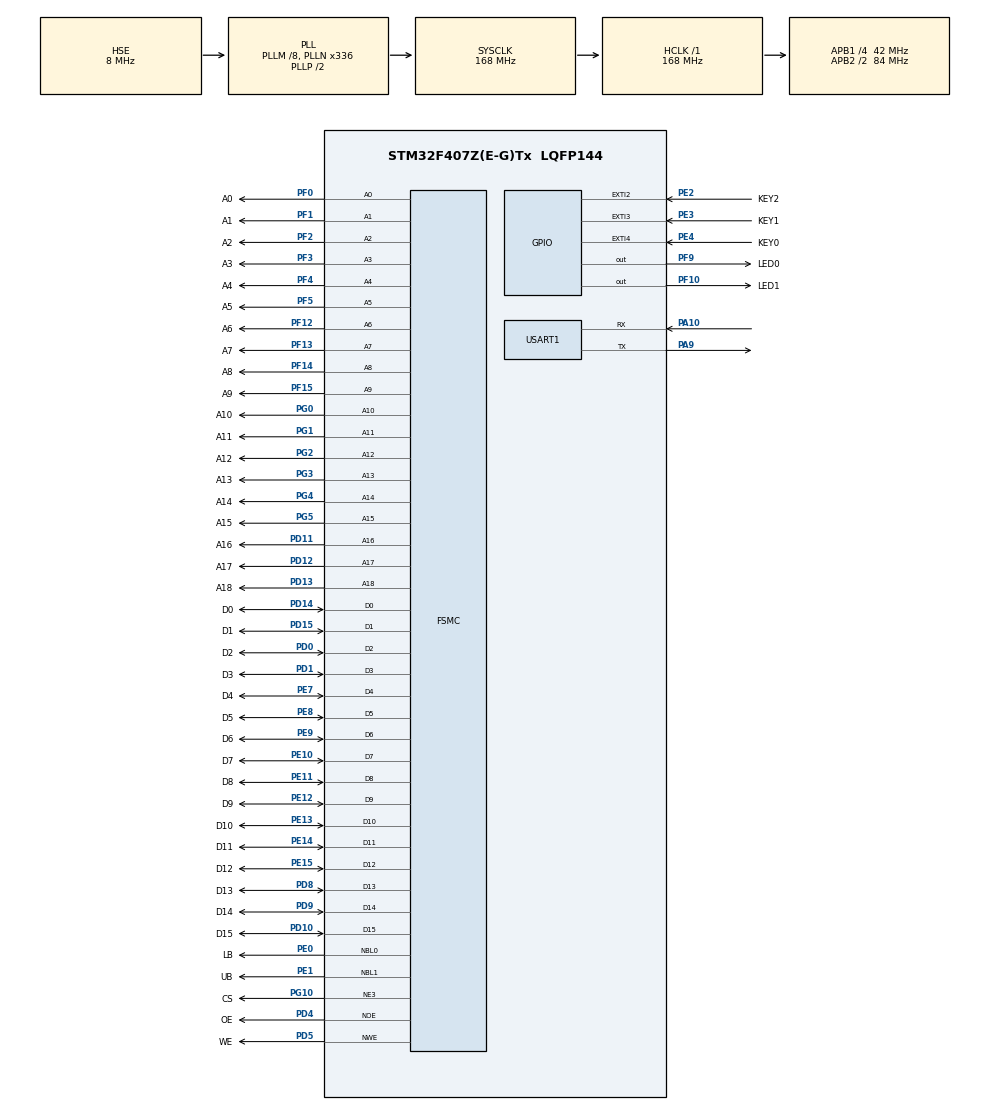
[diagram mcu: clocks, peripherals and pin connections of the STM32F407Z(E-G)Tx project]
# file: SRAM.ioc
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FSMC.AddressSetupTime1=2
FSMC.BusTurnAroundDuration1=0
FSMC.DataSetupTime1=8
FSMC.ExtendedMode1=FSMC_EXTENDED_MODE_DISABLE
FSMC.WriteOperation1=FSMC_WRITE_OPERATION_ENABLE
Mcu.Family=STM32F4
Mcu.Name=STM32F407Z(E-G)Tx
Mcu.Package=LQFP144
NVIC.EXTI2_IRQn=true\:1\:1\:true\:false\:true\:true\:true
NVIC.EXTI3_IRQn=true\:1\:1\:true\:false\:true\:true\:true
NVIC.EXTI4_IRQn=true\:1\:1\:true\:false\:true\:true\:true
NVIC.PriorityGroup=NVIC_PRIORITYGROUP_2
PA10.Mode=Asynchronous
PA10.Signal=USART1_RX
PA13.Mode=Serial_Wire
PA13.Signal=SYS_JTMS-SWDIO
PA14.Mode=Serial_Wire
PA14.Signal=SYS_JTCK-SWCLK
PA9.Mode=Asynchronous
PA9.Signal=USART1_TX
PD0.GPIO_Label=D2
PD0.GPIO_PuPd=GPIO_PULLUP
PD0.Signal=FSMC_D2_DA2
PD1.GPIO_Label=D3
PD1.GPIO_PuPd=GPIO_PULLUP
PD1.Signal=FSMC_D3_DA3
PD10.GPIO_Label=D15
PD10.GPIO_PuPd=GPIO_PULLUP
PD10.Signal=FSMC_D15_DA15
PD11.GPIO_Label=A16
PD11.GPIO_PuPd=GPIO_PULLUP
PD11.Signal=FSMC_A16_CLE
PD12.GPIO_Label=A17
PD12.GPIO_PuPd=GPIO_PULLUP
PD12.Signal=FSMC_A17_ALE
PD13.GPIO_Label=A18
PD13.GPIO_PuPd=GPIO_PULLUP
PD13.Signal=FSMC_A18
PD14.GPIO_Label=D0
PD14.GPIO_PuPd=GPIO_PULLUP
PD14.Signal=FSMC_D0_DA0
PD15.GPIO_Label=D1
PD15.GPIO_PuPd=GPIO_PULLUP
PD15.Signal=FSMC_D1_DA1
PD4.GPIO_Label=OE
PD4.GPIO_PuPd=GPIO_PULLUP
PD4.Signal=FSMC_NOE
PD5.GPIO_Label=WE
PD5.GPIO_PuPd=GPIO_PULLUP
PD5.Signal=FSMC_NWE
PD8.GPIO_Label=D13
PD8.GPIO_PuPd=GPIO_PULLUP
PD8.Signal=FSMC_D13_DA13
PD9.GPIO_Label=D14
PD9.GPIO_PuPd=GPIO_PULLUP
PD9.Signal=FSMC_D14_DA14
PE0.GPIO_Label=LB
PE0.GPIO_PuPd=GPIO_PULLUP
PE0.Signal=FSMC_NBL0
PE1.GPIO_Label=UB
PE1.GPIO_PuPd=GPIO_PULLUP
PE1.Signal=FSMC_NBL1
PE10.GPIO_Label=D7
PE10.GPIO_PuPd=GPIO_PULLUP
PE10.Signal=FSMC_D7_DA7
PE11.GPIO_Label=D8
PE11.GPIO_PuPd=GPIO_PULLUP
PE11.Signal=FSMC_D8_DA8
PE12.GPIO_Label=D9
PE12.GPIO_PuPd=GPIO_PULLUP
PE12.Signal=FSMC_D9_DA9
PE13.GPIO_Label=D10
PE13.GPIO_PuPd=GPIO_PULLUP
PE13.Signal=FSMC_D10_DA10
PE14.GPIO_Label=D11
PE14.GPIO_PuPd=GPIO_PULLUP
PE14.Signal=FSMC_D11_DA11
PE15.GPIO_Label=D12
PE15.GPIO_PuPd=GPIO_PULLUP
PE15.Signal=FSMC_D12_DA12
PE2.GPIO_Label=KEY2
PE2.GPIO_ModeDefaultEXTI=GPIO_MODE_IT_FALLING
PE2.GPIO_PuPd=GPIO_PULLUP
PE2.Signal=GPXTI2
PE3.GPIO_Label=KEY1
PE3.GPIO_ModeDefaultEXTI=GPIO_MODE_IT_FALLING
PE3.GPIO_PuPd=GPIO_PULLUP
PE3.Signal=GPXTI3
PE4.GPIO_Label=KEY0
PE4.GPIO_ModeDefaultEXTI=GPIO_MODE_IT_FALLING
PE4.GPIO_PuPd=GPIO_PULLUP
PE4.Signal=GPXTI4
PE7.GPIO_Label=D4
PE7.GPIO_PuPd=GPIO_PULLUP
PE7.Signal=FSMC_D4_DA4
PE8.GPIO_Label=D5
PE8.GPIO_PuPd=GPIO_PULLUP
PE8.Signal=FSMC_D5_DA5
PE9.GPIO_Label=D6
PE9.GPIO_PuPd=GPIO_PULLUP
PE9.Signal=FSMC_D6_DA6
PF0.GPIO_Label=A0
PF0.GPIO_PuPd=GPIO_PULLUP
PF0.Signal=FSMC_A0
PF1.GPIO_Label=A1
PF1.GPIO_PuPd=GPIO_PULLUP
PF1.Signal=FSMC_A1
PF10.GPIO_Label=LED1
PF10.GPIO_PuPd=GPIO_PULLUP
PF10.GPIO_Speed=GPIO_SPEED_FREQ_HIGH
PF10.PinState=GPIO_PIN_SET
PF10.Signal=GPIO_Output
PF12.GPIO_Label=A6
PF12.GPIO_PuPd=GPIO_PULLUP
PF12.Signal=FSMC_A6
PF13.GPIO_Label=A7
PF13.GPIO_PuPd=GPIO_PULLUP
PF13.Signal=FSMC_A7
PF14.GPIO_Label=A8
PF14.GPIO_PuPd=GPIO_PULLUP
PF14.Signal=FSMC_A8
PF15.GPIO_Label=A9
PF15.GPIO_PuPd=GPIO_PULLUP
PF15.Signal=FSMC_A9
PF2.GPIO_Label=A2
PF2.GPIO_PuPd=GPIO_PULLUP
PF2.Signal=FSMC_A2
PF3.GPIO_Label=A3
PF3.GPIO_PuPd=GPIO_PULLUP
PF3.Signal=FSMC_A3
PF4.GPIO_Label=A4
PF4.GPIO_PuPd=GPIO_PULLUP
PF4.Signal=FSMC_A4
PF5.GPIO_Label=A5
PF5.GPIO_PuPd=GPIO_PULLUP
PF5.Signal=FSMC_A5
PF9.GPIO_Label=LED0
PF9.GPIO_PuPd=GPIO_PULLUP
PF9.GPIO_Speed=GPIO_SPEED_FREQ_HIGH
PF9.PinState=GPIO_PIN_SET
PF9.Signal=GPIO_Output
PG0.GPIO_Label=A10
PG0.GPIO_PuPd=GPIO_PULLUP
PG0.Signal=FSMC_A10
PG1.GPIO_Label=A11
PG1.GPIO_PuPd=GPIO_PULLUP
PG1.Signal=FSMC_A11
PG10.GPIO_Label=CS
PG10.GPIO_PuPd=GPIO_PULLUP
PG10.Mode=NorPsramChipSelect3_1
PG10.Signal=FSMC_NE3
PG2.GPIO_Label=A12
PG2.GPIO_PuPd=GPIO_PULLUP
PG2.Signal=FSMC_A12
PG3.GPIO_Label=A13
PG3.GPIO_PuPd=GPIO_PULLUP
PG3.Signal=FSMC_A13
PG4.GPIO_Label=A14
PG4.GPIO_PuPd=GPIO_PULLUP
PG4.Signal=FSMC_A14
PG5.GPIO_Label=A15
PG5.GPIO_PuPd=GPIO_PULLUP
PG5.Signal=FSMC_A15
PH0-OSC_IN.Mode=HSE-External-Oscillator
PH0-OSC_IN.Signal=RCC_OSC_IN
PH1-OSC_OUT.Mode=HSE-External-Oscillator
PH1-OSC_OUT.Signal=RCC_OSC_OUT
ProjectManager.HeapSize=0x200
ProjectManager.StackSize=0x400
ProjectManager.TargetToolchain=MDK-ARM V5
RCC.48MHZClocksFreq_Value=84000000
RCC.AHBFreq_Value=168000000
RCC.APB1CLKDivider=RCC_HCLK_DIV4
RCC.APB1Freq_Value=42000000
RCC.APB1TimFreq_Value=84000000
RCC.APB2CLKDivider=RCC_HCLK_DIV2
RCC.APB2Freq_Value=84000000
RCC.APB2TimFreq_Value=168000000
RCC.CortexFreq_Value=168000000
RCC.HCLKFreq_Value=168000000
RCC.HSE_VALUE=8000000
RCC.HSI_VALUE=16000000
RCC.LSE_VALUE=32768
RCC.PLLM=8
RCC.PLLN=336
RCC.PLLSourceVirtual=RCC_PLLSOURCE_HSE
RCC.SYSCLKFreq_VALUE=168000000
RCC.SYSCLKSource=RCC_SYSCLKSOURCE_PLLCLK
RCC.VCOOutputFreq_Value=336000000
SH.FSMC_A0.0=FSMC_A0,19b-a1
SH.FSMC_A1.0=FSMC_A1,19b-a1
SH.FSMC_A10.0=FSMC_A10,19b-a1
SH.FSMC_A11.0=FSMC_A11,19b-a1
SH.FSMC_A12.0=FSMC_A12,19b-a1
SH.FSMC_A13.0=FSMC_A13,19b-a1
SH.FSMC_A14.0=FSMC_A14,19b-a1
SH.FSMC_A15.0=FSMC_A15,19b-a1
SH.FSMC_A16_CLE.0=FSMC_A16,19b-a1
SH.FSMC_A17_ALE.0=FSMC_A17,19b-a1
SH.FSMC_A18.0=FSMC_A18,19b-a1
SH.FSMC_A2.0=FSMC_A2,19b-a1
SH.FSMC_A3.0=FSMC_A3,19b-a1
SH.FSMC_A4.0=FSMC_A4,19b-a1
SH.FSMC_A5.0=FSMC_A5,19b-a1
SH.FSMC_A6.0=FSMC_A6,19b-a1
SH.FSMC_A7.0=FSMC_A7,19b-a1
SH.FSMC_A8.0=FSMC_A8,19b-a1
SH.FSMC_A9.0=FSMC_A9,19b-a1
SH.FSMC_D0_DA0.0=FSMC_D0,16b-d1
SH.FSMC_D10_DA10.0=FSMC_D10,16b-d1
SH.FSMC_D11_DA11.0=FSMC_D11,16b-d1
SH.FSMC_D12_DA12.0=FSMC_D12,16b-d1
SH.FSMC_D13_DA13.0=FSMC_D13,16b-d1
SH.FSMC_D14_DA14.0=FSMC_D14,16b-d1
SH.FSMC_D15_DA15.0=FSMC_D15,16b-d1
SH.FSMC_D1_DA1.0=FSMC_D1,16b-d1
SH.FSMC_D2_DA2.0=FSMC_D2,16b-d1
SH.FSMC_D3_DA3.0=FSMC_D3,16b-d1
SH.FSMC_D4_DA4.0=FSMC_D4,16b-d1
SH.FSMC_D5_DA5.0=FSMC_D5,16b-d1
SH.FSMC_D6_DA6.0=FSMC_D6,16b-d1
SH.FSMC_D7_DA7.0=FSMC_D7,16b-d1
SH.FSMC_D8_DA8.0=FSMC_D8,16b-d1
SH.FSMC_D9_DA9.0=FSMC_D9,16b-d1
SH.FSMC_NBL0.0=FSMC_NBL0,2ByteEnable1
SH.FSMC_NBL1.0=FSMC_NBL1,2ByteEnable1
SH.FSMC_NOE.0=FSMC_NOE,Sram1
SH.FSMC_NWE.0=FSMC_NWE,Sram1
USART1.VirtualMode=VM_ASYNC
board=custom

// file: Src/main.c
/* USER CODE BEGIN Header */
/**
  ******************************************************************************
  * @file           : main.c
  * @brief          : Main program body
  ******************************************************************************
  * @attention
  *
  * <h2><center>&copy; Copyright (c) 2024 STMicroelectronics.
  * All rights reserved.</center></h2>
  *
  * This software component is licensed by ST under BSD 3-Clause license,
  * the "License"; You may not use this file except in compliance with the
  * License. You may obtain a copy of the License at:
  *                        opensource.org/licenses/BSD-3-Clause
  *
  ******************************************************************************
  */
/* USER CODE END Header */

#include "main.h"
#include "usart.h"
#include "gpio.h"
#include "fsmc.h"

/* USER CODE BEGIN Includes */
#include "sram.h"
#include "exti.h"
/* USER CODE END Includes */

/* USER CODE BEGIN PV */
/* 使用SRAM空间开辟数组，用于测试*/
/* 测试用数组, 起始地址为: SRAM_BASE_ADDR */
#if (__ARMCC_VERSION >= 6010050)  //判断编译器版本是否大于等于 6010050
uint32_t g_test_buffer[BUFFER_SIZE] __attribute__((section(".bss.ARM.__at_0x68000000")));  //将数组放置在地址 0x68000000 Bank1的存储块3(FSMC_NE3)地址范围: 0X6800 0000 ~ 0X6BFF FFFF
#else
uint32_t g_test_buffer[BUFFER_SIZE] __attribute__((at(SRAM_BASE_ADDR)));  //将数组放置在 SRAM_BASE_ADDR
#endif

uint32_t ts;
/* USER CODE END PV */

void SystemClock_Config(void);

int main(void)
{

  /* MCU Configuration--------------------------------------------------------*/

  /* Reset of all peripherals, Initializes the Flash interface and the Systick. */
  HAL_Init();

  /* Configure the system clock */
  SystemClock_Config();

  /* Initialize all configured peripherals */
  MX_GPIO_Init();
  MX_USART1_UART_Init();
  MX_FSMC_Init();
  /* USER CODE BEGIN 2 */
	//给SRAM中开辟的数组赋值

	for (ts = 0; ts < BUFFER_SIZE; ts++){
		g_test_buffer[ts] = ts;         // 预存测试数据 [0:262143]
	}
	printf("Test buffer data evaluationed down!\n");

	/*
	for (ts = 0; ts < BUFFER_SIZE; ts++){
		if(ts != g_test_buffer[ts]){
			printf("%d is error, %d\n", ts, g_test_buffer[ts]);
		}
			//printf("%u ", g_test_buffer[ts]);         // 打印测试数据
	}
	printf("\n");
	*/
  /* USER CODE END 2 */

  /* Infinite loop */
  /* USER CODE BEGIN WHILE */
  while (1)
  {
		HAL_GPIO_TogglePin(LED1_GPIO_Port, LED1_Pin);  //LED1翻转
		HAL_Delay(100);
    /* USER CODE END WHILE */

  }
}

void SystemClock_Config(void)
{
  RCC_OscInitTypeDef RCC_OscInitStruct = {0};
  RCC_ClkInitTypeDef RCC_ClkInitStruct = {0};

  /** Configure the main internal regulator output voltage
  */
  __HAL_RCC_PWR_CLK_ENABLE();
  __HAL_PWR_VOLTAGESCALING_CONFIG(PWR_REGULATOR_VOLTAGE_SCALE1);
  /** Initializes the CPU, AHB and APB busses clocks
  */
  RCC_OscInitStruct.OscillatorType = RCC_OSCILLATORTYPE_HSE;
  RCC_OscInitStruct.HSEState = RCC_HSE_ON;
  RCC_OscInitStruct.PLL.PLLState = RCC_PLL_ON;
  RCC_OscInitStruct.PLL.PLLSource = RCC_PLLSOURCE_HSE;
  RCC_OscInitStruct.PLL.PLLM = 8;
  RCC_OscInitStruct.PLL.PLLN = 336;
  RCC_OscInitStruct.PLL.PLLP = RCC_PLLP_DIV2;
  RCC_OscInitStruct.PLL.PLLQ = 4;
  if (HAL_RCC_OscConfig(&RCC_OscInitStruct) != HAL_OK)
  {
    Error_Handler();
  }
  /** Initializes the CPU, AHB and APB busses clocks
  */
  RCC_ClkInitStruct.ClockType = RCC_CLOCKTYPE_HCLK|RCC_CLOCKTYPE_SYSCLK
                              |RCC_CLOCKTYPE_PCLK1|RCC_CLOCKTYPE_PCLK2;
  RCC_ClkInitStruct.SYSCLKSource = RCC_SYSCLKSOURCE_PLLCLK;
  RCC_ClkInitStruct.AHBCLKDivider = RCC_SYSCLK_DIV1;
  RCC_ClkInitStruct.APB1CLKDivider = RCC_HCLK_DIV4;
  RCC_ClkInitStruct.APB2CLKDivider = RCC_HCLK_DIV2;

  if (HAL_RCC_ClockConfig(&RCC_ClkInitStruct, FLASH_LATENCY_5) != HAL_OK)
  {
    Error_Handler();
  }
}

void Error_Handler(void)
{
}

/************************ (C) COPYRIGHT STMicroelectronics *****END OF FILE****/
